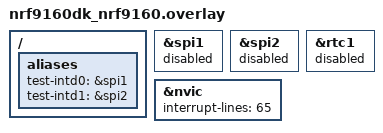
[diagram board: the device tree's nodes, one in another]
/*
 * Copyright (c) 2024 Bjarki Arge Andreasen
 *
 * SPDX-License-Identifier: Apache-2.0
 */

/ {
	aliases {
		test-intd0 = &spi1;
		test-intd1 = &spi2;
	};
};

&spi1 {
	status = "reserved";
};

&spi2 {
	status = "reserved";
};

&rtc1 {
	status = "reserved";
};

&nvic {
	interrupt-lines = <65>;
};
